# MKW41Z4 register map
Vendor: Freescale Semiconductor, Inc.; Series: Kinetis_W; File version: 1.6
CPU: CM0PLUS r0p0, little endian, no MPU, no FPU, VTOR, 2 interrupt priority bits
Registers are 16-bit, read-write, no defined reset value unless marked. A register's access mark holds for its fields unless they carry their own. Offsets are from the block's base; [hi:lo] are bit positions; {n}, {i} and the like mark numbered series; 'fields as' and 'values as' point back to an identical list.

## RX_DIG — XCVR_RX_DIG
Base 0x4005C000
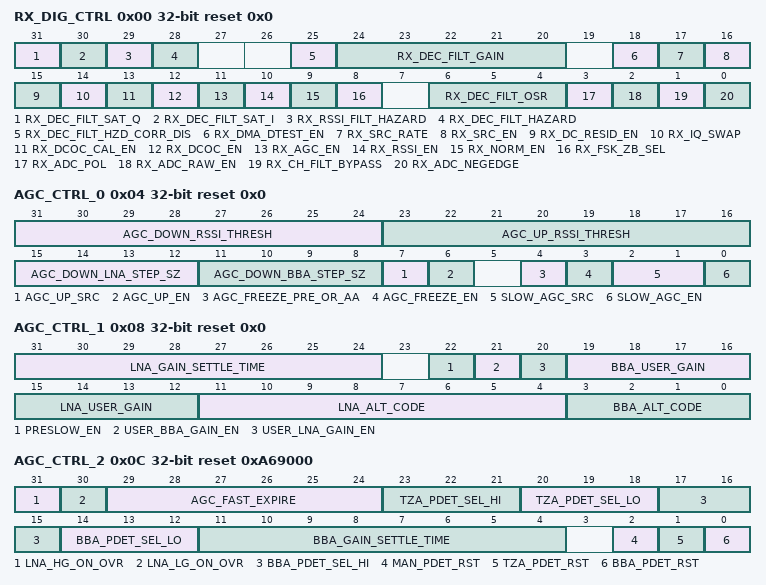
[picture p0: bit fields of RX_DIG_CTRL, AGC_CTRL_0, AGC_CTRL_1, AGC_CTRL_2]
0x00 RX_DIG_CTRL 32-bit reset 0x0 — RX Digital Control
  [31] RX_DEC_FILT_SAT_Q ro — Decimator output, saturation detected for Q channel
    0=A saturation condition has not occurred; 1=A saturation condition has occurred
  [30] RX_DEC_FILT_SAT_I ro — Decimator output, saturation detected for I channel
    values as RX_DEC_FILT_SAT_Q
  [29] RX_RSSI_FILT_HAZARD ro — Decimator output for RSSI, hazard condition detected
    0=A hazard condition has not been detected; 1=A hazard condition has been detected
  [28] RX_DEC_FILT_HAZARD ro — Decimator output, hazard condition detected
    values as RX_RSSI_FILT_HAZARD
  [25] RX_DEC_FILT_HZD_CORR_DIS — Decimator filter hazard correction disable
  [24:20] RX_DEC_FILT_GAIN — Decimation Filter Fractional Gain
  [18] RX_DMA_DTEST_EN — RX DMA and DTEST enable
  [17] RX_SRC_RATE — RX Sample Rate Converter Rate Selections
    0=SRC is configured for a First Order Hold rate of 8/13; 1=SRC is configured for a Zero Order Hold rate of 12/13
  [16] RX_SRC_EN — RX Sample Rate Converter Enable
    0=SRC is disabled; 1=SRC is enabled
  [15] RX_DC_RESID_EN — DC Residual Enable
    0=DC Residual block is disabled; 1=DC Residual block is enabled
  [14] RX_IQ_SWAP
    0=IQ swap is disabled; 1=IQ swap is enabled
  [13] RX_DCOC_CAL_EN — DCOC Calibration Enable
    0=DCOC calibration is disabled; 1=DCOC calibration is enabled
  [12] RX_DCOC_EN — DCOC Enable
    0=DCOC is disabled; 1=DCOC is enabled
  [11] RX_AGC_EN — AGC Global Enable
    0=AGC is disabled; 1=AGC is enabled
  [10] RX_RSSI_EN — RSSI Measurement Enable
    0=RSSI measurement is disabled; 1=RSSI measurement is enabled
  [9] RX_NORM_EN — Normalizer Enable
    0=Normalizer is disabled; 1=Normalizer is enabled
  [8] RX_FSK_ZB_SEL — FSK / 802.15.4 demodulator select
    0=FSK demodulator; 1=802.15.4 demodulator
  [6:4] RX_DEC_FILT_OSR — Decimation Filter Oversampling
    0=OSR 4; 1=OSR 8; 2=OSR 16; 4=OSR 32; 3=OSR 6; 5=OSR 12; 6=OSR 24
  [3] RX_ADC_POL — Receive ADC Polarity
    0=ADC output of 1'b0 maps to -1, 1'b1 maps to +1 (default); 1=ADC output of 1'b0 maps to +1, 1'b1 maps to -1
  [2] RX_ADC_RAW_EN — ADC Raw Mode selection
    0=Normal operation; 1=The decimation filter's 12bit output consists of ADC samples in the 8 LSBs. This is for test purposes only to observe ADC output via XCVR DMA or DTEST.
  [1] RX_CH_FILT_BYPASS — Receive Channel Filter Bypass
    0=Channel filter is enabled; 1=Disable and bypass channel filter
  [0] RX_ADC_NEGEDGE — Receive ADC Negative Edge Selection
    0=Register ADC data on positive edge of clock; 1=Register ADC data on negative edge of clock
0x04 AGC_CTRL_0 32-bit reset 0x0 — AGC Control 0
  [31:24] AGC_DOWN_RSSI_THRESH — AGC DOWN RSSI Threshold
  [23:16] AGC_UP_RSSI_THRESH — AGC UP RSSI Threshold
  [15:12] AGC_DOWN_LNA_STEP_SZ
  [11:8] AGC_DOWN_BBA_STEP_SZ
  [7] AGC_UP_SRC — AGC Up Source
    0=PDET LO; 1=RSSI
  [6] AGC_UP_EN — AGC Up Enable
  [4] AGC_FREEZE_PRE_OR_AA — AGC Freeze Source Selection
    0=Access Address match (for active protocol); 1=Preamble Detect (for active protocol)
  [3] AGC_FREEZE_EN — AGC Freeze Enable
  [2:1] SLOW_AGC_SRC — Slow AGC Source Selection
    0=Access Address match (for active protocol); 1=Preamble Detect (for active protocol); 2=Fast AGC expire timer
  [0] SLOW_AGC_EN — Slow AGC Enable
0x08 AGC_CTRL_1 32-bit reset 0x0 — AGC Control 1
  [31:24] LNA_GAIN_SETTLE_TIME
  [22] PRESLOW_EN — Pre-slow Enable
    0=Pre-slow is disabled; 1=Pre-slow is enabled
  [21] USER_BBA_GAIN_EN — User BBA Gain Enable
  [20] USER_LNA_GAIN_EN — User LNA Gain Enable
  [19:16] BBA_USER_GAIN
  [15:12] LNA_USER_GAIN
  [11:4] LNA_ALT_CODE
  [3:0] BBA_ALT_CODE
0x0C AGC_CTRL_2 32-bit reset 0xA69000 — AGC Control 2
  [31] LNA_HG_ON_OVR — LNA_HG_ON override
  [30] LNA_LG_ON_OVR — LNA_LG_ON override
  [29:24] AGC_FAST_EXPIRE
  [23:21] TZA_PDET_SEL_HI — TZA PDET Threshold High
    0=0.60V; 1=0.63V; 2=0.66V; 3=0.69V; 4=0.72V; 5=0.75V; 6=0.78V; 7=0.81V
  [20:18] TZA_PDET_SEL_LO — TZA PDET Threshold Low
    0=0.600V; 1=0.615V; 2=0.630V; 3=0.645V; 4=0.660V; 5=0.675V; 6=0.690V; 7=0.705V
  [17:15] BBA_PDET_SEL_HI — BBA PDET Threshold High
    0=0.600V; 1=0.795V; 2=0.900V; 3=0.945V; 4=1.005V; 5=1.050V; 6=1.095V; 7=1.155V
  [14:12] BBA_PDET_SEL_LO — BBA PDET Threshold Low
    values as TZA_PDET_SEL_LO
  [11:4] BBA_GAIN_SETTLE_TIME
  [2] MAN_PDET_RST — MAN PDET Reset
    0=The peak detector reset signals are controlled automatically by the AGC; 1=The BBA_PDET_RST and TZA_PDET_RST are used to manually control the peak detector reset signals
  [1] TZA_PDET_RST — TZA PDET Reset
  [0] BBA_PDET_RST — BBA PDET Reset
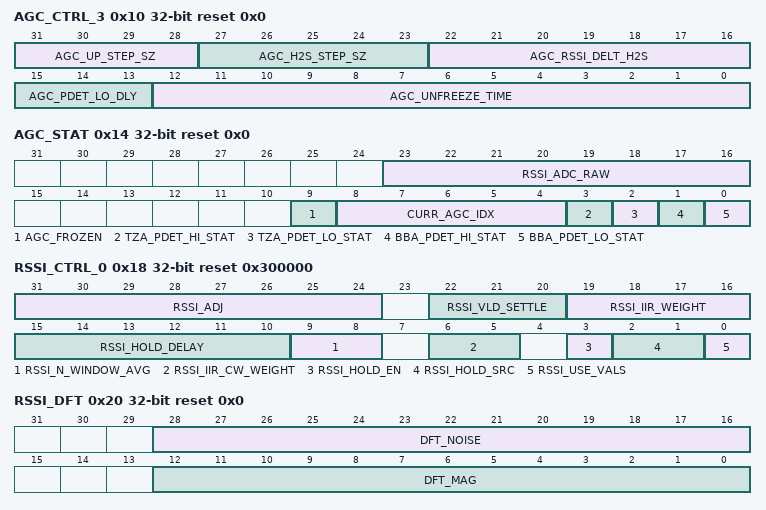
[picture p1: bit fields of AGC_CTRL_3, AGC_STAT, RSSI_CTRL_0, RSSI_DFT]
0x10 AGC_CTRL_3 32-bit reset 0x0 — AGC Control 3
  [31:28] AGC_UP_STEP_SZ — AGC Up Step Size
  [27:23] AGC_H2S_STEP_SZ
  [22:16] AGC_RSSI_DELT_H2S
  [15:13] AGC_PDET_LO_DLY — AGC Peak Detect Low Delay
  [12:0] AGC_UNFREEZE_TIME
0x14 AGC_STAT 32-bit ro reset 0x0 — AGC Status
  [23:16] RSSI_ADC_RAW — ADC RAW RSSI Reading
  [9] AGC_FROZEN — AGC Frozen Status
    0=AGC is not frozen; 1=AGC is frozen
  [8:4] CURR_AGC_IDX — Current AGC Gain Index
  [3] TZA_PDET_HI_STAT — TZA Peak Detector High Status
  [2] TZA_PDET_LO_STAT — TZA Peak Detector Low Status
  [1] BBA_PDET_HI_STAT — BBA Peak Detector High Status
  [0] BBA_PDET_LO_STAT — BBA Peak Detector Low Status
0x18 RSSI_CTRL_0 32-bit reset 0x300000 — RSSI Control 0
  [31:24] RSSI_ADJ — RSSI Adjustment
  [22:20] RSSI_VLD_SETTLE — RSSI Valid Settle
  [19:16] RSSI_IIR_WEIGHT — RSSI IIR Weighting
    0=Bypass; 1=1/2; 2=1/4; 3=1/8; 4=1/16; 5=1/32
  [15:10] RSSI_HOLD_DELAY
  [9:8] RSSI_N_WINDOW_AVG — RSSI N Window Average
    0=No averaging; 1=Averaging window length is 2 samples; 2=Averaging window length is 4 samples; 3=Averaging window length is 8 samples
  [6:5] RSSI_IIR_CW_WEIGHT — RSSI IIR CW Weighting
    0=Bypass; 1=1/8; 2=1/16; 3=1/32
  [3] RSSI_HOLD_EN — RSSI Hold Enable
  [2:1] RSSI_HOLD_SRC — RSSI Hold Source Selection
    0=Access Address match; 1=Preamble Detect; 3=802.15.4 LQI done (1=freeze, 0=run AGC)
  [0] RSSI_USE_VALS — RSSI Values Selection
0x1C RSSI_CTRL_1 32-bit ro reset 0x0 — RSSI Control 1
  [31:24] RSSI_OUT — RSSI Reading
0x20 RSSI_DFT 32-bit ro reset 0x0
  [28:16] DFT_NOISE — RSSI MAG
  [12:0] DFT_MAG — RSSI MAG
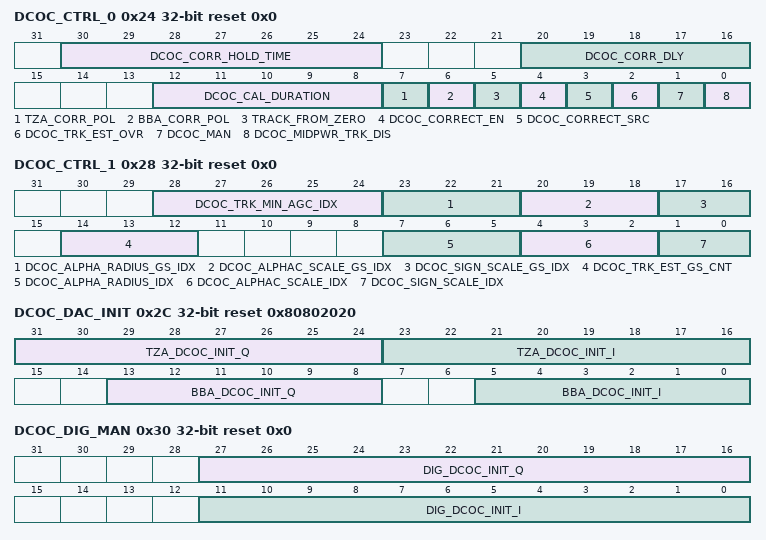
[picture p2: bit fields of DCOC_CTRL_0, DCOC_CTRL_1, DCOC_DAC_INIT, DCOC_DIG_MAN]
0x24 DCOC_CTRL_0 32-bit reset 0x0 — DCOC Control 0
  [30:24] DCOC_CORR_HOLD_TIME — DCOC Correction Hold Time
    127=The DC correction is not frozen
  [20:16] DCOC_CORR_DLY — DCOC Correction Delay
  [12:8] DCOC_CAL_DURATION — DCOC Calibration Duration
  [7] TZA_CORR_POL — TZA Correction Polarity
    0=Normal polarity; 1=Negative polarity. This should be set if the ADC output is inverted, or if the TZA DACs were implemented with negative polarity.
  [6] BBA_CORR_POL — BBA Correction Polarity
    0=Normal polarity; 1=Negative polarity. This should be set if the ADC output is inverted, or if the BBA DACs were implemented with negative polarity.
  [5] TRACK_FROM_ZERO
    0=Track from current I/Q sample; 1=Track from zero
  [4] DCOC_CORRECT_EN — DCOC Correction Enable
    0=Correction disabled. The DCOC will not correct the DC offset.; 1=Correction enabled. The DCOC will use the TZA and BBA DACs, and apply digital corrections (if DCOC_CORRECT_SRC=1) to correct the DC offset.
  [3] DCOC_CORRECT_SRC — DCOC Corrector Source
    0=If correction is enabled, the DCOC will use only the DCOC calibration table to correct the DC offset; 1=If correction is enabled, the DCOC will use the DCOC calibration table and then the tracking estimator to correct the DC offset
  [2] DCOC_TRK_EST_OVR — Override for the DCOC tracking estimator
    0=The tracking estimator is enabled only as needed by the corrector; 1=The tracking estimator remains enabled whenever the DCOC is active
  [1] DCOC_MAN — DCOC Manual Override
  [0] DCOC_MIDPWR_TRK_DIS — DCOC Mid Power Tracking Disable
    0=Tracking corrections are enabled as determined by DCOC_CORRECT_SRC and DCOC_TRK_MIN_AGC_IDX; 1=Tracking corrections are disabled when either the TZA or BBA lo peak detector asserts
0x28 DCOC_CTRL_1 32-bit reset 0x0 — DCOC Control 1
  [28:24] DCOC_TRK_MIN_AGC_IDX — DCOC Tracking Minimum AGC Table Index
  [23:21] DCOC_ALPHA_RADIUS_GS_IDX — Alpha-R Scaling for Gearshift
    0=1; 1=1/2; 2=1/4; 3=1/8; 4=1/16; 5=1/32; 6=1/64
  [20:18] DCOC_ALPHAC_SCALE_GS_IDX — DCOC Alpha-C Scaling for Gearshift
    0=1/2; 1=1/4; 2=1/8; 3=1/16; 4=1/32; 5=1/64
  [17:16] DCOC_SIGN_SCALE_GS_IDX — DCOC Sign Scaling for Gearshift
    0=1/8; 1=1/16; 2=1/32; 3=1/64
  [14:12] DCOC_TRK_EST_GS_CNT — DCOC Tracking Estimator Gearshift Count
  [7:5] DCOC_ALPHA_RADIUS_IDX — Alpha-R Scaling
    0=1; 1=1/2; 2=1/4; 3=1/8; 4=1/16; 5=1/32; 6=1/64
  [4:2] DCOC_ALPHAC_SCALE_IDX — DCOC Alpha-C Scaling
    0=1/2; 1=1/4; 2=1/8; 3=1/16; 4=1/32; 5=1/64
  [1:0] DCOC_SIGN_SCALE_IDX — DCOC Sign Scaling
    0=1/8; 1=1/16; 2=1/32; 3=1/64
0x2C DCOC_DAC_INIT 32-bit reset 0x80802020 — DCOC DAC Initialization
  [31:24] TZA_DCOC_INIT_Q — DCOC TZA Init Q
  [23:16] TZA_DCOC_INIT_I — DCOC TZA Init I
  [13:8] BBA_DCOC_INIT_Q — DCOC BBA Init Q
  [5:0] BBA_DCOC_INIT_I — DCOC BBA Init I
0x30 DCOC_DIG_MAN 32-bit reset 0x0 — DCOC Digital Correction Manual Override
  [27:16] DIG_DCOC_INIT_Q — DCOC DIG Init Q
  [11:0] DIG_DCOC_INIT_I — DCOC DIG Init I
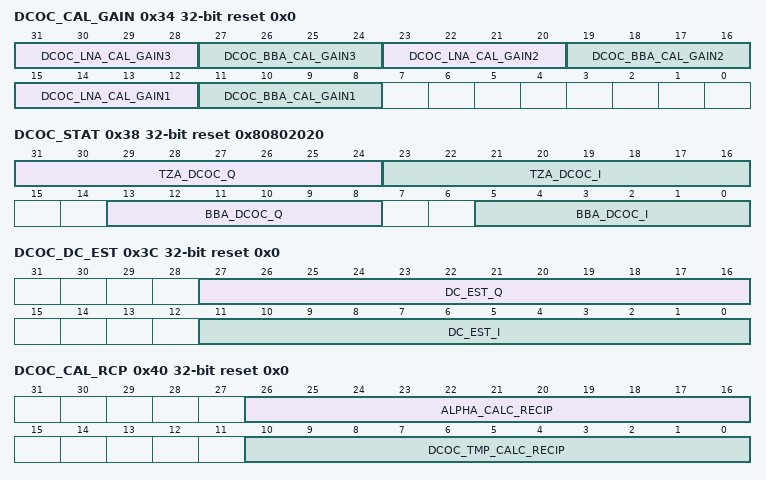
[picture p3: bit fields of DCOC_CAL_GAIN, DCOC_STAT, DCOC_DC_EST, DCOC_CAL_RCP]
0x34 DCOC_CAL_GAIN 32-bit reset 0x0 — DCOC Calibration Gain
  [31:28] DCOC_LNA_CAL_GAIN3 — DCOC LNA Calibration Gain 3
  [27:24] DCOC_BBA_CAL_GAIN3 — DCOC BBA Calibration Gain 3
  [23:20] DCOC_LNA_CAL_GAIN2 — DCOC LNA Calibration Gain 2
  [19:16] DCOC_BBA_CAL_GAIN2 — DCOC BBA Calibration Gain 2
  [15:12] DCOC_LNA_CAL_GAIN1 — DCOC LNA Calibration Gain 1
  [11:8] DCOC_BBA_CAL_GAIN1 — DCOC BBA Calibration Gain 1
0x38 DCOC_STAT 32-bit ro reset 0x80802020 — DCOC Status
  [31:24] TZA_DCOC_Q — DCOC TZA DAC Q
  [23:16] TZA_DCOC_I — DCOC TZA DAC I
  [13:8] BBA_DCOC_Q — DCOC BBA DAC Q
  [5:0] BBA_DCOC_I — DCOC BBA DAC I
0x3C DCOC_DC_EST 32-bit ro reset 0x0 — DCOC DC Estimate
  [27:16] DC_EST_Q — DCOC DC Estimate Q
  [11:0] DC_EST_I — DCOC DC Estimate I
0x40 DCOC_CAL_RCP 32-bit reset 0x0 — DCOC Calibration Reciprocals
  [26:16] ALPHA_CALC_RECIP — Alpha Calculation Reciprocal
  [10:0] DCOC_TMP_CALC_RECIP — DCOC Calculation Reciprocal
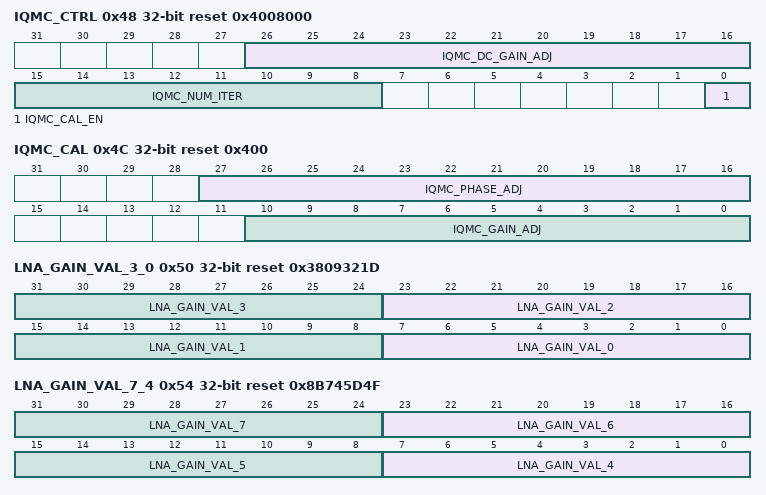
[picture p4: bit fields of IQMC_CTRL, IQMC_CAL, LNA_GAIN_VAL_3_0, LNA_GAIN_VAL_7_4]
0x48 IQMC_CTRL 32-bit reset 0x4008000 — IQMC Control
  [26:16] IQMC_DC_GAIN_ADJ — IQ Mismatch Correction DC Gain Coeff
  [15:8] IQMC_NUM_ITER — IQ Mismatch Cal Num Iter
  [0] IQMC_CAL_EN — IQ Mismatch Cal Enable
0x4C IQMC_CAL 32-bit reset 0x400 — IQMC Calibration
  [27:16] IQMC_PHASE_ADJ — IQ Mismatch Correction Phase Coeff
  [10:0] IQMC_GAIN_ADJ — IQ Mismatch Correction Gain Coeff
0x50 LNA_GAIN_VAL_3_0 32-bit reset 0x3809321D — LNA_GAIN Step Values 3..0
  [8n+7:8n] LNA_GAIN_VAL_{n} (n=0..3) — LNA_GAIN step {n}
0x54 LNA_GAIN_VAL_7_4 32-bit reset 0x8B745D4F — LNA_GAIN Step Values 7..4
  [8n-25:8n-32] LNA_GAIN_VAL_{n} (n=4..7) — LNA_GAIN step {n}
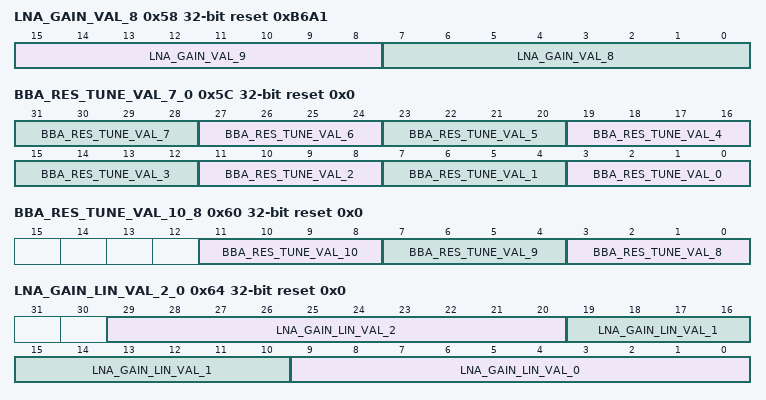
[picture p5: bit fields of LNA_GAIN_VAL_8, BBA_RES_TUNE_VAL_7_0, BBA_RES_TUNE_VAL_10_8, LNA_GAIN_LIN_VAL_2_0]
0x58 LNA_GAIN_VAL_8 32-bit reset 0xB6A1 — LNA_GAIN Step Values 8
  [15:8] LNA_GAIN_VAL_9 — LNA_GAIN step 9
  [7:0] LNA_GAIN_VAL_8 — LNA_GAIN step 8
0x5C BBA_RES_TUNE_VAL_7_0 32-bit reset 0x0 — BBA Resistor Tune Values 7..0
  [4n+3:4n] BBA_RES_TUNE_VAL_{n} (n=0..7) — BBA Resistor Tune Step {n}
0x60 BBA_RES_TUNE_VAL_10_8 32-bit reset 0x0 — BBA Resistor Tune Values 10..8
  [11:8] BBA_RES_TUNE_VAL_10 — BBA Resistor Tune Step 10
  [7:4] BBA_RES_TUNE_VAL_9 — BBA Resistor Tune Step 9
  [3:0] BBA_RES_TUNE_VAL_8 — BBA Resistor Tune Step 8
0x64 LNA_GAIN_LIN_VAL_2_0 32-bit reset 0x0 — LNA Linear Gain Values 2..0
  [29:20] LNA_GAIN_LIN_VAL_2 — LNA Linear Gain Step 2
  [19:10] LNA_GAIN_LIN_VAL_1 — LNA Linear Gain Step 1
  [9:0] LNA_GAIN_LIN_VAL_0 — LNA Linear Gain Step 0
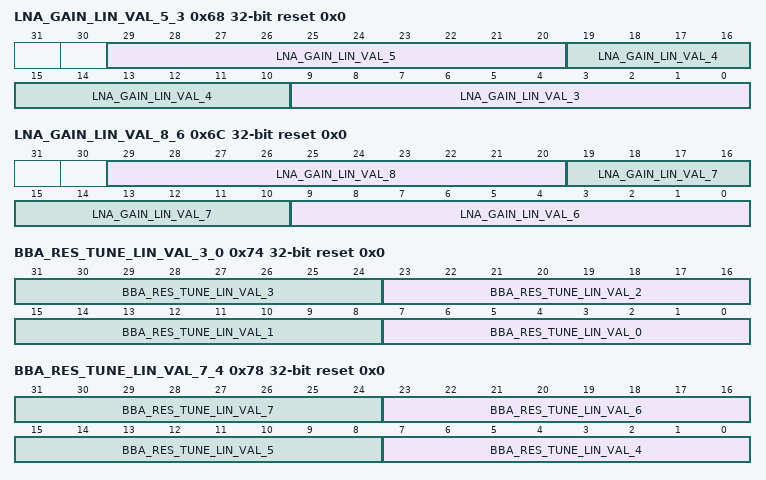
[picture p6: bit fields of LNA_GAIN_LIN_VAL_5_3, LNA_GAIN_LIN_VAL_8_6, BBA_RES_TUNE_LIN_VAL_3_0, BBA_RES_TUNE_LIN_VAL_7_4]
0x68 LNA_GAIN_LIN_VAL_5_3 32-bit reset 0x0 — LNA Linear Gain Values 5..3
  [29:20] LNA_GAIN_LIN_VAL_5 — LNA Linear Gain Step 5
  [19:10] LNA_GAIN_LIN_VAL_4 — LNA Linear Gain Step 4
  [9:0] LNA_GAIN_LIN_VAL_3 — LNA Linear Gain Step 3
0x6C LNA_GAIN_LIN_VAL_8_6 32-bit reset 0x0 — LNA Linear Gain Values 8..6
  [29:20] LNA_GAIN_LIN_VAL_8 — LNA Linear Gain Step 8
  [19:10] LNA_GAIN_LIN_VAL_7 — LNA Linear Gain Step 7
  [9:0] LNA_GAIN_LIN_VAL_6 — LNA Linear Gain Step 6
0x70 LNA_GAIN_LIN_VAL_9 32-bit reset 0x0 — LNA Linear Gain Values 9
  [9:0] LNA_GAIN_LIN_VAL_9 — LNA Linear Gain Step 9
0x74 BBA_RES_TUNE_LIN_VAL_3_0 32-bit reset 0x0 — BBA Resistor Tune Values 3..0
  [8n+7:8n] BBA_RES_TUNE_LIN_VAL_{n} (n=0..3) — BBA Resistor Tune Linear Gain Step {n}
0x78 BBA_RES_TUNE_LIN_VAL_7_4 32-bit reset 0x0 — BBA Resistor Tune Values 7..4
  [8n-25:8n-32] BBA_RES_TUNE_LIN_VAL_{n} (n=4..7) — BBA Resistor Tune Linear Gain Step {n}
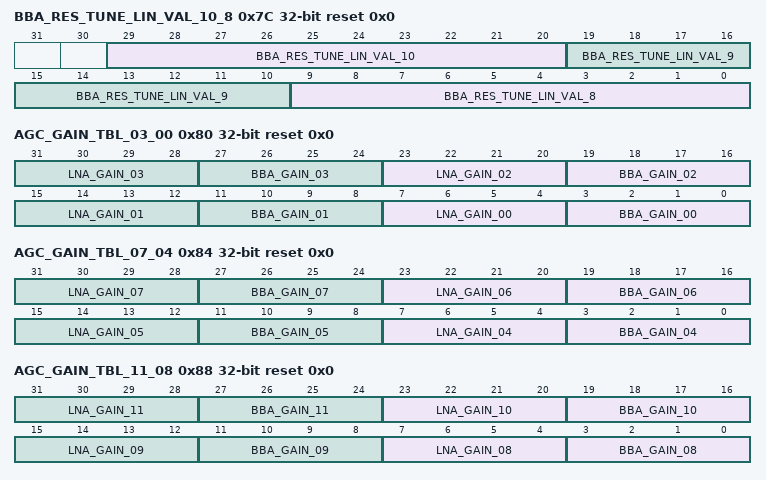
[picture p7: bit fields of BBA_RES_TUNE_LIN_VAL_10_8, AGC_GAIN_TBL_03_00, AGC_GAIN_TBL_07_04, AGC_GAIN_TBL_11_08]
0x7C BBA_RES_TUNE_LIN_VAL_10_8 32-bit reset 0x0 — BBA Resistor Tune Values 10..8
  [29:20] BBA_RES_TUNE_LIN_VAL_10 — BBA Resistor Tune Linear Gain Step 10
  [19:10] BBA_RES_TUNE_LIN_VAL_9 — BBA Resistor Tune Linear Gain Step 9
  [9:0] BBA_RES_TUNE_LIN_VAL_8 — BBA Resistor Tune Linear Gain Step 8
0x80 AGC_GAIN_TBL_03_00 32-bit reset 0x0 — AGC Gain Tables Step 03..00
  [8n+7:8n+4] LNA_GAIN_{n:02} (n=0..3), [8n+3:8n] BBA_GAIN_{n:02} (n=0..3)
0x84 AGC_GAIN_TBL_07_04 32-bit reset 0x0 — AGC Gain Tables Step 07..04
  [8n-25:8n-28] LNA_GAIN_{n:02} (n=4..7), [8n-29:8n-32] BBA_GAIN_{n:02} (n=4..7)
0x88 AGC_GAIN_TBL_11_08 32-bit reset 0x0 — AGC Gain Tables Step 11..08
  [8n-57:8n-60] LNA_GAIN_{n:02} (n=8..11), [8n-61:8n-64] BBA_GAIN_{n:02} (n=8..11)
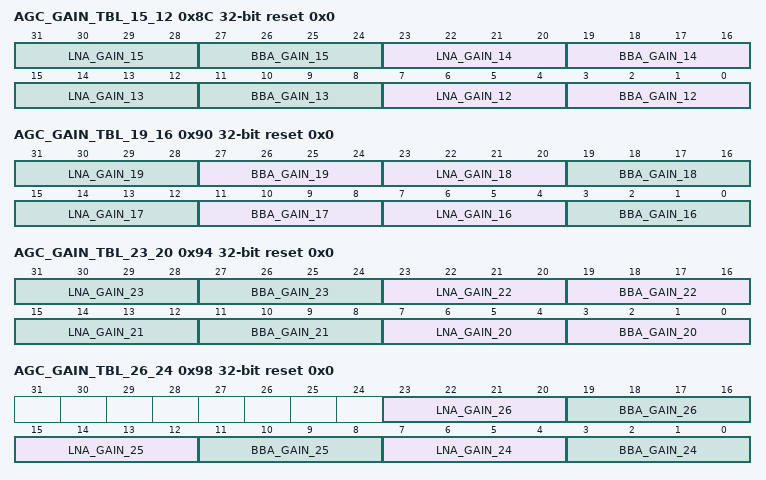
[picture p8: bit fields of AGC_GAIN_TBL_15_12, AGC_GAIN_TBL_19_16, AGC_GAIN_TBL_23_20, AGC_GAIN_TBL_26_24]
0x8C AGC_GAIN_TBL_15_12 32-bit reset 0x0 — AGC Gain Tables Step 15..12
  [8n-89:8n-92] LNA_GAIN_{n} (n=12..15), [8n-93:8n-96] BBA_GAIN_{n} (n=12..15)
0x90 AGC_GAIN_TBL_19_16 32-bit reset 0x0 — AGC Gain Tables Step 19..16
  [8n-121:8n-124] LNA_GAIN_{n} (n=16..19)
  [27:24] BBA_GAIN_19 — BBA Gain 193
  [19:16] BBA_GAIN_18
  [11:8] BBA_GAIN_17
  [3:0] BBA_GAIN_16
0x94 AGC_GAIN_TBL_23_20 32-bit reset 0x0 — AGC Gain Tables Step 23..20
  [8n-153:8n-156] LNA_GAIN_{n} (n=20..23), [8n-157:8n-160] BBA_GAIN_{n} (n=20..23)
0x98 AGC_GAIN_TBL_26_24 32-bit reset 0x0 — AGC Gain Tables Step 26..24
  [23:20] LNA_GAIN_26, [19:16] BBA_GAIN_26, [15:12] LNA_GAIN_25, [11:8] BBA_GAIN_25, [7:4] LNA_GAIN_24, [3:0] BBA_GAIN_24
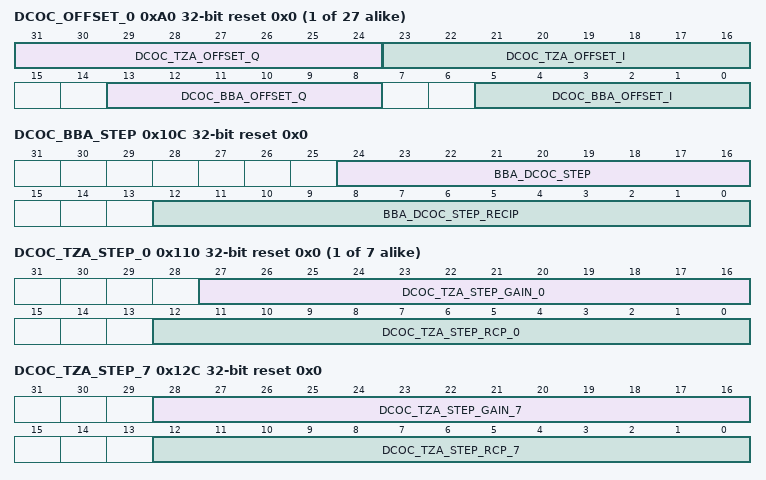
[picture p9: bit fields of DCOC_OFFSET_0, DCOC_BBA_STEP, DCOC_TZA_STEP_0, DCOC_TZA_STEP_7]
{0xA0+4i} DCOC_OFFSET_{i} 32-bit reset 0x0 (i=0..26) — DCOC Offset
  [31:24] DCOC_TZA_OFFSET_Q — DCOC TZA Q-channel offset
  [23:16] DCOC_TZA_OFFSET_I — DCOC TZA I-channel offset
  [13:8] DCOC_BBA_OFFSET_Q — DCOC BBA Q-channel offset
  [5:0] DCOC_BBA_OFFSET_I — DCOC BBA I-channel offset
0x10C DCOC_BBA_STEP 32-bit reset 0x0 — DCOC BBA DAC Step
  [24:16] BBA_DCOC_STEP — DCOC BBA Step Size
  [12:0] BBA_DCOC_STEP_RECIP — DCOC BBA Reciprocal of Step Size
{0x110+4i} DCOC_TZA_STEP_{i} 32-bit reset 0x0 (i=0..6) — DCOC TZA DAC Step {i}
  [27:16] DCOC_TZA_STEP_GAIN_{i}, [12:0] DCOC_TZA_STEP_RCP_{i}
0x12C DCOC_TZA_STEP_7 32-bit reset 0x0 — DCOC TZA DAC Step 7
  [28:16] DCOC_TZA_STEP_GAIN_7, [12:0] DCOC_TZA_STEP_RCP_7
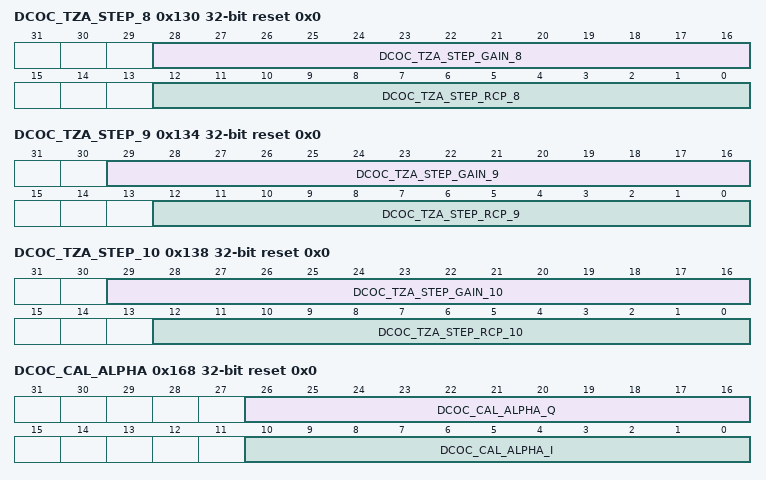
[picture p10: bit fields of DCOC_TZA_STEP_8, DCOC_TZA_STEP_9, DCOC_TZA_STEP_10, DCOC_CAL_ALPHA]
0x130 DCOC_TZA_STEP_8 32-bit reset 0x0 — DCOC TZA DAC Step 5
  [28:16] DCOC_TZA_STEP_GAIN_8, [12:0] DCOC_TZA_STEP_RCP_8
0x134 DCOC_TZA_STEP_9 32-bit reset 0x0 — DCOC TZA DAC Step 9
  [29:16] DCOC_TZA_STEP_GAIN_9, [12:0] DCOC_TZA_STEP_RCP_9
0x138 DCOC_TZA_STEP_10 32-bit reset 0x0 — DCOC TZA DAC Step 10
  [29:16] DCOC_TZA_STEP_GAIN_10, [12:0] DCOC_TZA_STEP_RCP_10
0x168 DCOC_CAL_ALPHA 32-bit ro reset 0x0 — DCOC Calibration Alpha
  [26:16] DCOC_CAL_ALPHA_Q
  [10:0] DCOC_CAL_ALPHA_I — DCOC Calibration I-channel ALPHA constant
0x16C DCOC_CAL_BETA_Q 32-bit ro reset 0x0 — DCOC Calibration Beta Q
  [16:0] DCOC_CAL_BETA_Q
0x170 DCOC_CAL_BETA_I 32-bit ro reset 0x0 — DCOC Calibration Beta I
  [16:0] DCOC_CAL_BETA_I
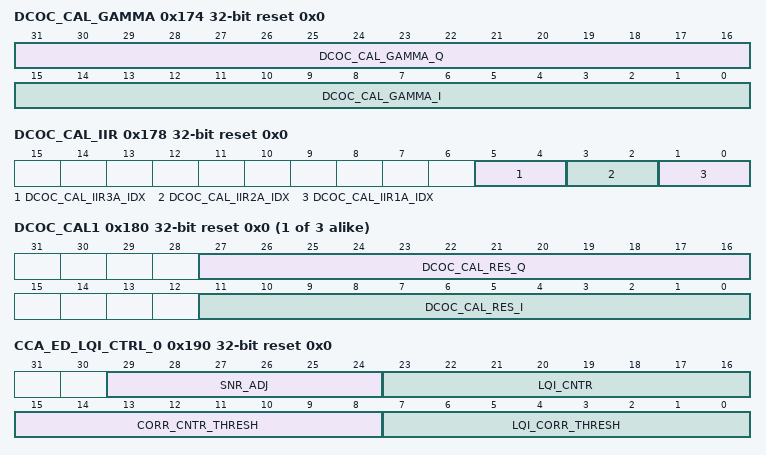
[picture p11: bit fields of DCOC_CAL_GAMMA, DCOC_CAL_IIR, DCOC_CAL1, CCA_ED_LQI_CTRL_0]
0x174 DCOC_CAL_GAMMA 32-bit ro reset 0x0 — DCOC Calibration Gamma
  [31:16] DCOC_CAL_GAMMA_Q, [15:0] DCOC_CAL_GAMMA_I
0x178 DCOC_CAL_IIR 32-bit reset 0x0 — DCOC Calibration IIR
  [5:4] DCOC_CAL_IIR3A_IDX — DCOC Calibration IIR 3A Index
    0=1/4; 1=1/8; 2=1/16; 3=1/32
  [3:2] DCOC_CAL_IIR2A_IDX — DCOC Calibration IIR 2A Index
    0=1/1; 1=1/4; 2=1/8; 3=1/16
  [1:0] DCOC_CAL_IIR1A_IDX — DCOC Calibration IIR 1A Index
    0=1/1; 1=1/4; 2=1/8; 3=1/16
{0x17C+4i} DCOC_CAL{i} 32-bit ro reset 0x0 (i=1..3) — DCOC Calibration Result
  [27:16] DCOC_CAL_RES_Q — DCOC Calibration Result - Q Channel
  [11:0] DCOC_CAL_RES_I — DCOC Calibration Result - I Channel
0x190 CCA_ED_LQI_CTRL_0 32-bit reset 0x0 — RX_DIG CCA ED LQI Control Register 0
  [29:24] SNR_ADJ — SNR calculation adjustment
  [23:16] LQI_CNTR — LQI Counter
  [15:8] CORR_CNTR_THRESH — Correlation Count Threshold
  [7:0] LQI_CORR_THRESH — LQI Correlation Threshold
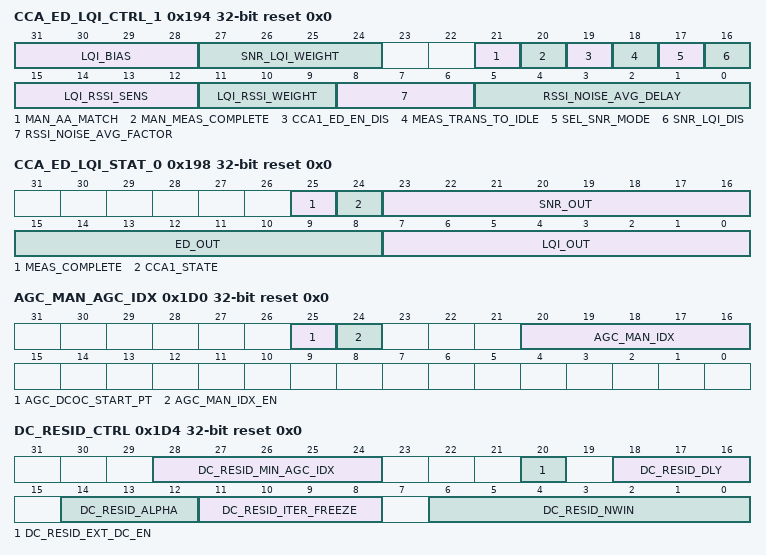
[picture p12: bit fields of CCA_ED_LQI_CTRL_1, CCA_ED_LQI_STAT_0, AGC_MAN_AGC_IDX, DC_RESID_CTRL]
0x194 CCA_ED_LQI_CTRL_1 32-bit reset 0x0 — RX_DIG CCA ED LQI Control Register 1
  [31:28] LQI_BIAS
  [27:24] SNR_LQI_WEIGHT
    0=0.0; 1=1.0; 2=1.125; 3=1.25; 4=1.375; 5=1.5; 6=1.625; 7=1.75; 8=1.875; 9=2.0; 10=2.125; 11=2.25; 12=2.375; 13=2.5; 14=2.625; 15=2.75
  [21] MAN_AA_MATCH — Manual AA Match
    0=Normal operation; 1=Manually asserts the AA match signal for the RX_DIG CCA/ED/LQI and AGC blocks. Intended to be used only for debug.
  [20] MAN_MEAS_COMPLETE — Manual measurement complete
    0=Normal operation; 1=Manually asserts the measurement complete signal for the RX_DIG CCA/ED/LQI blocks. Intended to be used only for debug.
  [19] CCA1_ED_EN_DIS — CCA1_ED_EN Disable
    0=Normal operation; 1=CCA1_ED_EN input is disabled
  [18] MEAS_TRANS_TO_IDLE — Measurement Transition to IDLE
    0=Module transitions to RSSI state; 1=Module transitions to IDLE state
  [17] SEL_SNR_MODE — Select SNR Mode
    0=SNR estimate; 1=Mapped correlation magnitude
  [16] SNR_LQI_DIS — SNR LQI Disable
    0=Normal operation; 1=The RX_DIG CCA/ED/LQI block ignores the AA match input which starts an LQI measurement
  [15:12] LQI_RSSI_SENS — LQI RSSI Sensitivity
  [11:9] LQI_RSSI_WEIGHT
    0=2.0; 1=2.125; 2=2.25; 3=2.375; 4=2.5; 5=2.625; 6=2.75; 7=2.875
  [8:6] RSSI_NOISE_AVG_FACTOR — RSSI Noise Averaging Factor
    0=1; 1=64; 2=70; 3=128; 4=139; 5=256; 6=277; 7=512
  [5:0] RSSI_NOISE_AVG_DELAY — RSSI Noise Averaging Delay
0x198 CCA_ED_LQI_STAT_0 32-bit ro reset 0x0 — RX_DIG CCA ED LQI Status Register 0
  [25] MEAS_COMPLETE — Measurement Complete
  [24] CCA1_STATE
  [23:16] SNR_OUT — SNR output
  [15:8] ED_OUT — ED output
  [7:0] LQI_OUT — LQI output
0x1A0 RX_CHF_COEF_0 32-bit reset 0x0 — Receive Channel Filter Coefficient 0
  [5:0] RX_CH_FILT_H0 — RX Channel Filter Coefficient 0
0x1A4 RX_CHF_COEF_1 32-bit reset 0x0 — Receive Channel Filter Coefficient 1
  [5:0] RX_CH_FILT_H1 — RX Channel Filter Coefficient 1
{0x1A0+4i} RX_CHF_COEF_{i} 32-bit reset 0x0 (i=2..5) — Receive Channel Filter Coefficient {i}
  [6:0] RX_CH_FILT_H{i} — RX Channel Filter Coefficient {i}
0x1B8 RX_CHF_COEF_6 32-bit reset 0x0 — Receive Channel Filter Coefficient 6
  [7:0] RX_CH_FILT_H6 — RX Channel Filter Coefficient 6
0x1BC RX_CHF_COEF_7 32-bit reset 0x0 — Receive Channel Filter Coefficient 7
  [7:0] RX_CH_FILT_H7 — RX Channel Filter Coefficient 7
0x1C0 RX_CHF_COEF_8 32-bit reset 0x0 — Receive Channel Filter Coefficient 8
  [8:0] RX_CH_FILT_H8 — RX Channel Filter Coefficient 8
0x1C4 RX_CHF_COEF_9 32-bit reset 0x0 — Receive Channel Filter Coefficient 9
  [8:0] RX_CH_FILT_H9 — RX Channel Filter Coefficient 9
0x1C8 RX_CHF_COEF_10 32-bit reset 0x0 — Receive Channel Filter Coefficient 10
  [9:0] RX_CH_FILT_H10 — RX Channel Filter Coefficient 10
0x1CC RX_CHF_COEF_11 32-bit reset 0x0 — Receive Channel Filter Coefficient 11
  [9:0] RX_CH_FILT_H11 — RX Channel Filter Coefficient 11
0x1D0 AGC_MAN_AGC_IDX 32-bit reset 0x0 — AGC Manual AGC Index
  [25] AGC_DCOC_START_PT — AGC DCOC Start Point
  [24] AGC_MAN_IDX_EN — AGC Manual Index Enable
  [20:16] AGC_MAN_IDX — AGC Manual Index
0x1D4 DC_RESID_CTRL 32-bit reset 0x0 — DC Residual Control
  [28:24] DC_RESID_MIN_AGC_IDX wo — DC Residual Minimum AGC Table Index
  [20] DC_RESID_EXT_DC_EN — DC Residual External DC Enable
  [18:16] DC_RESID_DLY — DC Residual Delay
  [14:12] DC_RESID_ALPHA — DC Residual Alpha
  [11:8] DC_RESID_ITER_FREEZE — DC Residual Iteration Freeze
  [6:0] DC_RESID_NWIN — DC Residual NWIN
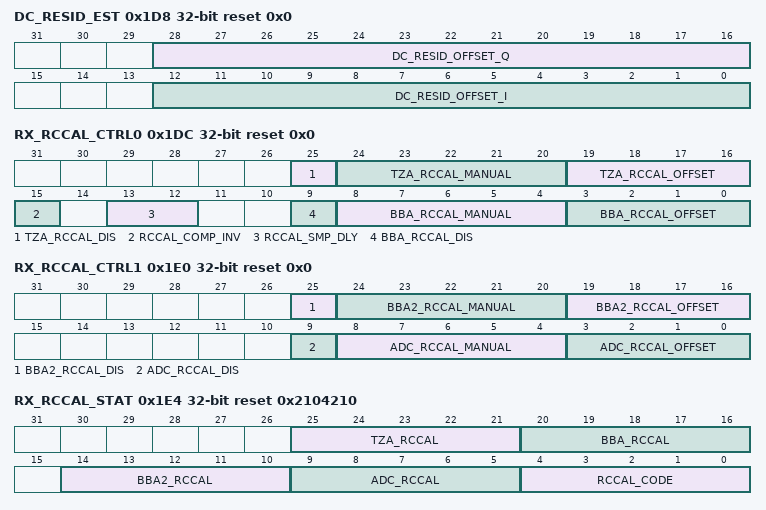
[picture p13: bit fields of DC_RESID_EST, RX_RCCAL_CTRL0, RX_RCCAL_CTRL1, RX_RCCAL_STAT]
0x1D8 DC_RESID_EST 32-bit ro reset 0x0 — DC Residual Estimate
  [28:16] DC_RESID_OFFSET_Q — DC Residual Offset Q
  [12:0] DC_RESID_OFFSET_I — DC Residual Offset I
0x1DC RX_RCCAL_CTRL0 32-bit reset 0x0 — RX RC Calibration Control0
  [25] TZA_RCCAL_DIS — TZA RC Calibration Disable
    0=TZA RC Calibration is enabled; 1=TZA RC Calibration is disabled
  [24:20] TZA_RCCAL_MANUAL — TZA RC Calibration manual value
  [19:16] TZA_RCCAL_OFFSET — TZA RC Calibration value offset
  [15] RCCAL_COMP_INV — RC Calibration comp_out Invert
    0=The comp_out signal polarity is NOT inverted; 1=The comp_out signal polarity is inverted
  [13:12] RCCAL_SMP_DLY — RC Calibration Sample Delay
    {v}=The comp_out signal is sampled {v} clk cycle after sample signal is deasserted (v=0..3)
  [9] BBA_RCCAL_DIS — BBA RC Calibration Disable
    0=BBA RC Calibration is enabled; 1=BBA RC Calibration is disabled
  [8:4] BBA_RCCAL_MANUAL — BBA RC Calibration manual value
  [3:0] BBA_RCCAL_OFFSET — BBA RC Calibration value offset
0x1E0 RX_RCCAL_CTRL1 32-bit reset 0x0 — RX RC Calibration Control1
  [25] BBA2_RCCAL_DIS — BBA2 RC Calibration Disable
    0=BBA2 RC Calibration is enabled; 1=BBA2 RC Calibration is disabled
  [24:20] BBA2_RCCAL_MANUAL — BBA2 RC Calibration manual value
  [19:16] BBA2_RCCAL_OFFSET — BBA2 RC Calibration value offset
  [9] ADC_RCCAL_DIS — ADC RC Calibration Disable
    0=ADC RC Calibration is enabled; 1=ADC RC Calibration is disabled
  [8:4] ADC_RCCAL_MANUAL — ADC RC Calibration manual value
  [3:0] ADC_RCCAL_OFFSET — ADC RC Calibration value offset
0x1E4 RX_RCCAL_STAT 32-bit ro reset 0x2104210 — RX RC Calibration Status
  [25:21] TZA_RCCAL — TZA RC Calibration
  [20:16] BBA_RCCAL — BBA RC Calibration
  [14:10] BBA2_RCCAL — BBA2 RC Calibration
  [9:5] ADC_RCCAL — ADC RC Calibration
  [4:0] RCCAL_CODE — RC Calibration code
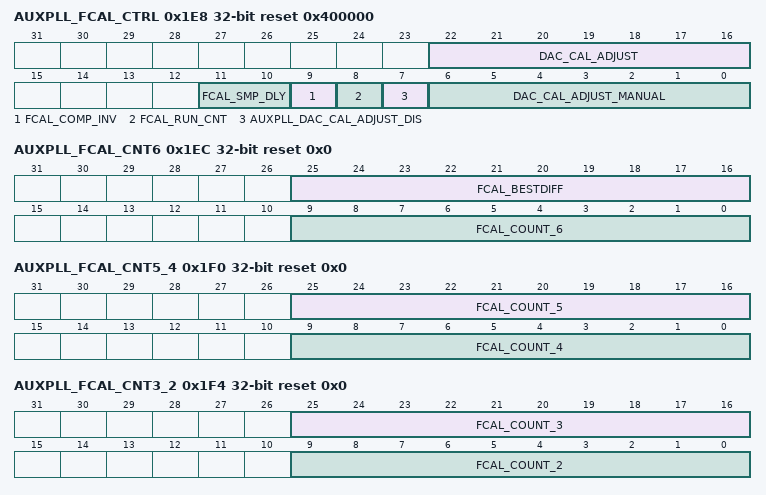
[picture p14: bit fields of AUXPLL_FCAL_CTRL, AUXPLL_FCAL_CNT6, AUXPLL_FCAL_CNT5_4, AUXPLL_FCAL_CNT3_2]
0x1E8 AUXPLL_FCAL_CTRL 32-bit reset 0x400000 — Aux PLL Frequency Calibration Control
  [22:16] DAC_CAL_ADJUST ro — Aux PLL DAC Calibration Adjust value
  [11:10] FCAL_SMP_DLY — Aux PLL Frequency Calibration Sample Delay
    {v}=The count signal is sampled {v+1} clk cycle after fcal_run signal is deasserted (v=0..3)
  [9] FCAL_COMP_INV — Aux PLL Frequency Calibration Comparison Invert
    0=(Default) The comparison associated with the count is not inverted; 1=The comparison associated with the count is inverted
  [8] FCAL_RUN_CNT — Aux PLL Frequency Calibration Run Count
    0=Run count is 256 clock cycles; 1=Run count is 512 clock cycles
  [7] AUXPLL_DAC_CAL_ADJUST_DIS — Aux PLL Frequency Calibration Disable
    0=Calibration is enabled; 1=Calibration is disabled
  [6:0] DAC_CAL_ADJUST_MANUAL — Aux PLL Frequency DAC Calibration Adjust Manual value
0x1EC AUXPLL_FCAL_CNT6 32-bit ro reset 0x0 — Aux PLL Frequency Calibration Count 6
  [25:16] FCAL_BESTDIFF — Aux PLL Frequency Calibration Best Difference
  [9:0] FCAL_COUNT_6 — Aux PLL Frequency Calibration Count 6
0x1F0 AUXPLL_FCAL_CNT5_4 32-bit ro reset 0x0 — Aux PLL Frequency Calibration Count 5 and 4
  [25:16] FCAL_COUNT_5 — Aux PLL Frequency Calibration Count 5
  [9:0] FCAL_COUNT_4 — Aux PLL Frequency Calibration Count 4
0x1F4 AUXPLL_FCAL_CNT3_2 32-bit ro reset 0x0 — Aux PLL Frequency Calibration Count 3 and 2
  [25:16] FCAL_COUNT_3 — Aux PLL Frequency Calibration Count 3
  [9:0] FCAL_COUNT_2 — Aux PLL Frequency Calibration Count 2
0x1F8 AUXPLL_FCAL_CNT1_0 32-bit ro reset 0x0 — Aux PLL Frequency Calibration Count 1 and 0
  [25:16] FCAL_COUNT_1 — Frequency Calibration Count 1
  [9:0] FCAL_COUNT_0 — Frequency Calibration Count 0
0x1FC RXDIG_DFT 32-bit reset 0x0
  [5] DFT_TONE_BBA_EN — DFT Tone Generator BBA Enable
    0=The DCOC controls the BBA DC offset correction DACs; 1=A tone is generated using the BBA DC offset correction DACs
  [4] DFT_TONE_TZA_EN — DFT Tone Generator TZA Enable
    0=The DCOC controls the TZA DC offset correction DACs; 1=A tone is generated using the TZA DC offset correction DACs
  [3] DFT_TONE_SCALE — DFT Tone Generator Scale
    0=The DFT tone generator uses 3/4 of the DC offset correction DAC range; 1=The DFT tone generator uses 1/2 of the DC offset correction DAC range
  [2:0] DFT_TONE_FREQ — DFT Tone Generator Frequency
    0=1/64 of the ref osc frequency (500kHz for 32MHz ref osc); 1=1/128 of the ref osc frequency (250kHz for 32MHz ref osc); 2=1/256 of the ref osc frequency (125kHz for 32MHz ref osc); 3=1/512 of the ref osc frequency (62.5kHz for 32MHz ref osc); 4=1/1024 of the ref osc frequency (31.25kHz for 32MHz ref osc)
